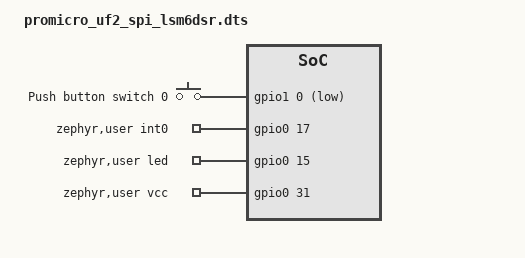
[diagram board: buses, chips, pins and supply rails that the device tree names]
// Copyright (c) 2024 Nordic Semiconductor ASA
// SPDX-License-Identifier: Apache-2.0

/dts-v1/;
#include "promicro_uf2.dts"

// Override pinctrl to match master branch configuration
&pinctrl {
	i2c0_default: i2c0_default {
		group1 {
			psels = <NRF_PSEL(TWIM_SDA, 0, 6)>, <NRF_PSEL(TWIM_SCL, 0, 8)>;
			bias-disable;
		};
	};

	i2c0_sleep: i2c0_sleep {
		group1 {
			psels = <NRF_PSEL(TWIM_SDA, 0, 6)>, <NRF_PSEL(TWIM_SCL, 0, 8)>;
			bias-disable;
			low-power-enable;
		};
	};

	spi3_default: spi3_default {
		group1 {
			psels = <NRF_PSEL(SPIM_MISO, 0, 24)>,
					<NRF_PSEL(SPIM_MOSI, 0, 6)>,
					<NRF_PSEL(SPIM_SCK, 0, 8)>;
		};
	};

	spi3_sleep: spi3_sleep {
		group1 {
			psels = <NRF_PSEL(SPIM_MISO, 0, 24)>,
					<NRF_PSEL(SPIM_MOSI, 0, 6)>,
					<NRF_PSEL(SPIM_SCK, 0, 8)>;
			low-power-enable;
		};
	};
};

/ {
	// Override button configuration to match master
	buttons {
		compatible = "gpio-keys";
		button0: button_0 {
			gpios = <&gpio1 0 (GPIO_PULL_UP | GPIO_ACTIVE_LOW)>;
			label = "Push button switch 0";
		};
	};

	aliases {
		sw0 = &button0;
		pwm-led0 = &pwm_led0;
	};

	// Use same GPIO configuration as master branch
	zephyr,user {
		int0-gpios = <&gpio0 17 0>;
		led-gpios = <&gpio0 15 GPIO_OPEN_SOURCE>;
		// clk-gpios = <&gpio0 20 GPIO_OPEN_DRAIN>; // Uncomment and set to
		vcc-gpios = <&gpio0 31 GPIO_ACTIVE_HIGH>;
	};
};

// Override SPI CS pin to match master
&spi3 {
	cs-gpios = <&gpio0 22 GPIO_ACTIVE_LOW>;
};

/delete-node/ &i2c0;2024 Nordic Semiconductor ASA
// SPDX-License-Identifier: Apache-2.0

/dts-v1/;
#include "promicro_uf2.dts"

// Use same GPIO configuration as master branch (with clk-gpios commented)
/ {
	zephyr,user {
		int0-gpios = <&gpio0 17 0>;
		led-gpios = <&gpio0 15 GPIO_OPEN_SOURCE>;
		// clk-gpios = <&gpio0 20 GPIO_OPEN_DRAIN>; // Uncomment and set to
    vcc-gpios = <&gpio0 31 GPIO_ACTIVE_HIGH>;
	};
};

/delete-node/ &i2c0;
